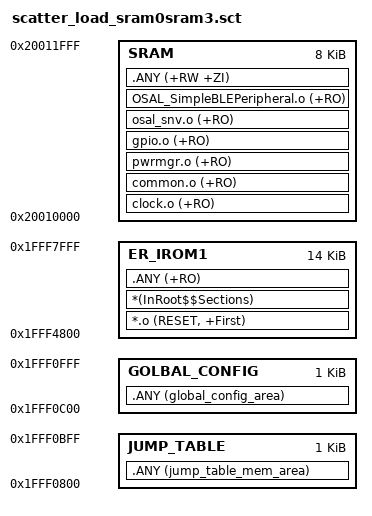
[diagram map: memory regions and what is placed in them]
; *************************************************************
; *** Scatter-Loading Description File generated by uVision ***
; *************************************************************
LR_IROM1 0x1fff4800 0x3800 {  ; load region size_region
  ER_IROM1 0x1fff4800 0x3800  {  ; load address = execution address
   *.o (RESET, +First)
   *(InRoot$$Sections)  
   .ANY (+RO)    
   ;.ANY (+RW +ZI)   
   ;main.o(+RW +ZI)
  }  
}

LR_IROM3 0x1fff8000 0x2000 { 
 SRAM 0x20010000 0x2000{
	clock.o (+RO)
	common.o (+RO) 	
	pwrmgr.o (+RO)
	gpio.o (+RO)
	osal_snv.o (+RO)
	
	OSAL_SimpleBLEPeripheral.o (+RO)
	.ANY (+RW +ZI)
 }  
}
 
LR_IROM2  0x1fff0800 0x00800 {
  JUMP_TABLE 0x1fff0800 0x00400  {
   .ANY (jump_table_mem_area) 	
  }
  GOLBAL_CONFIG 0x1fff0c00 0x00400  {
   .ANY (global_config_area) 	
  }  
 } 

